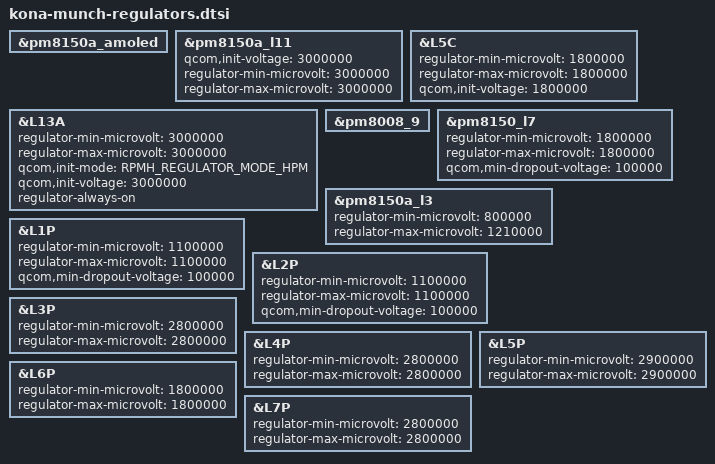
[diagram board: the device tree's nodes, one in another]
// SPDX-License-Identifier: GPL-2.0
/* Copyright (c) 2022, The Linux Foundation. All rights reserved.
 *
 * This program is free software; you can redistribute it and/or modify
 * it under the terms of the GNU General Public License version 2 and
 * only version 2 as published by the Free Software Foundation.
 *
 * This program is distributed in the hope that it will be useful,
 * but WITHOUT ANY WARRANTY; without even the implied warranty of
 * MERCHANTABILITY or FITNESS FOR A PARTICULAR PURPOSE.  See the
 * GNU General Public License for more details.
 */

/* Display */
&pm8150a_amoled {
	status = "ok";
};

&pm8150a_l11 {
	qcom,init-voltage = <3000000>;
	regulator-min-microvolt = <3000000>;
	regulator-max-microvolt = <3000000>;
};

/* Fingerprint */
&L13A {
	regulator-min-microvolt = <3000000>;
	regulator-max-microvolt = <3000000>;
	qcom,init-mode = <RPMH_REGULATOR_MODE_HPM>;
	qcom,init-voltage = <3000000>;
	regulator-always-on;
};

&L5C {
	regulator-min-microvolt = <1800000>;
	regulator-max-microvolt = <1800000>;
	qcom,init-voltage = <1800000>;
};

/* Camera */
&pm8008_9 {
	status = "ok";
};

&pm8150_l7 {
	regulator-min-microvolt = <1800000>;
	regulator-max-microvolt = <1800000>;
	qcom,min-dropout-voltage = <100000>;
};

&pm8150a_l3 {
	regulator-min-microvolt = <800000>;
	regulator-max-microvolt = <1210000>;
};

&L1P {
	regulator-min-microvolt = <1100000>;
	regulator-max-microvolt = <1100000>;
	qcom,min-dropout-voltage = <100000>;
};

&L2P {
	regulator-min-microvolt = <1100000>;
	regulator-max-microvolt = <1100000>;
	qcom,min-dropout-voltage = <100000>;
};

&L3P {
	regulator-min-microvolt = <2800000>;
	regulator-max-microvolt = <2800000>;
};

&L4P {
	regulator-min-microvolt = <2800000>;
	regulator-max-microvolt = <2800000>;
};

&L5P {
	regulator-min-microvolt = <2900000>;
	regulator-max-microvolt = <2900000>;
};

&L6P {
	regulator-min-microvolt = <1800000>;
	regulator-max-microvolt = <1800000>;
};

&L7P {
	regulator-min-microvolt = <2800000>;
	regulator-max-microvolt = <2800000>;
};
